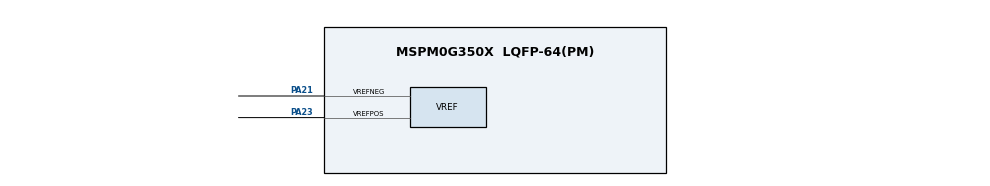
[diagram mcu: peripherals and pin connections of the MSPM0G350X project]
/**
 * @cliArgs --device "MSPM0G350X" --part "Default" --package "LQFP-64(PM)" --product "mspm0_sdk@2.07.00.06"
 * @versions {"tool":"1.25.0+4268"}
 */

/**
 * Import the modules used in this configuration.
 */
const Board         = scripting.addModule("/ti/driverlib/Board");
const DAC12         = scripting.addModule("/ti/driverlib/DAC12");
const SYSCTL        = scripting.addModule("/ti/driverlib/SYSCTL");
const VREF          = scripting.addModule("/ti/driverlib/VREF");
const ProjectConfig = scripting.addModule("/ti/project_config/ProjectConfig");

/**
 * Write custom configuration values to the imported modules.
 */
const gate8  = system.clockTree["MFPCLKGATE"];
gate8.enable = true;


DAC12.dacOutputPinEn     = true;
DAC12.dacAmplifier       = "ON";
DAC12.dacPosVREF         = "VEREFP";
DAC12.dacNegVREF         = "VEREFN";
DAC12.OutPinConfig.$name = "ti_driverlib_gpio_GPIOPinGeneric0";

SYSCTL.clockTreeEn           = true;
SYSCTL.forceDefaultClkConfig = true;
SYSCTL.MFPCLKEn              = true;

VREF.basicIntVolt                  = "DL_VREF_BUFCONFIG_OUTPUT_2_5V";
VREF.checkVREFReady                = true;
VREF.advClockConfigEnable          = true;
VREF.advClkSrc                     = "DL_VREF_CLOCK_BUSCLK";
VREF.basicVrefPins                 = "VREF+-";
VREF.vrefPosPinConfig.$name        = "ti_driverlib_gpio_GPIOPinGeneric1";
VREF.peripheral.$assign            = "VREF";
VREF.peripheral.vrefPosPin.$assign = "PA23";
VREF.peripheral.vrefNegPin.$assign = "PA21";
VREF.vrefNegPinConfig.$name        = "ti_driverlib_gpio_GPIOPinGeneric2";

/**
 * Pinmux solution for unlocked pins/peripherals. This ensures that minor changes to the automatic solver in a future
 * version of the tool will not impact the pinmux you originally saw.  These lines can be completely deleted in order to
 * re-solve from scratch.
 */
Board.peripheral.$suggestSolution          = "DEBUGSS";
Board.peripheral.swclkPin.$suggestSolution = "PA20";
Board.peripheral.swdioPin.$suggestSolution = "PA19";
DAC12.peripheral.$suggestSolution          = "DAC0";
DAC12.peripheral.OutPin.$suggestSolution   = "PA15";
